AUTOSAR XML (schema 00049)
package /Application/DltConfig
  dlt log channel to process mapping DltLogChannelToProcessMapping_KATECH_TO_KATECH: dlt-log-channel=KATECH, process=KATECH
package /Application/Executable
  executable KATECH: category=APPLICATION_LEVEL, logging-behavior=USES-LOGGING, reporting-behavior=REPORTS-EXECUTION-STATE, version=1.0.0
    root sw component prototype AA: application-type=KATECH
package /Application/Manifest
  service instance to port prototype mapping KATECH_AA_RPortRearCurtain: port-prototype=AA.RPortRearCurtain, service-instance=EEVP_KATECH_Consumer_RearCurtain
  service instance to port prototype mapping KATECH_AA_RPortRoa: port-prototype=AA.RPortRoa, service-instance=EEVP_KATECH_Consumer_SoaRoa
  service instance to port prototype mapping KATECH_AA_RPortSubscriptionManagement: port-prototype=AA.RPortSubscriptionManagement, service-instance=EEVP_KATECH_Consumer_SubscriptionManagement
package /Application/Package/KATECH/SoftwareCluster_1_0_0
  software cluster KATECH_SoftwareCluster: category=APPLICATION_LAYER, contained-ar-element=KATECH, contained-package-element=[KATECH_AA_RPortRearCurtain, KATECH_AA_RPortRoa], contained-process=KATECH, vendor-id=102, vendor-signature=ParaCertificate, version=1.0.0
package /Application/Package/KATECH/SoftwarePackage
  software package KATECH_InstallSoftwarePackage_1_0_0: action-type=INSTALL, compressed-software-package-size=0, maximum-supported-ucm-version=1.0.0, minimum-supported-ucm-version=1.0.0, packager-id=102, packager-signature=ParaCertificate, post-verification-reboot=false, pre-activation-reboot=false, software-cluster=KATECH_SoftwareCluster, uncompressed-software-cluster-size=0
  software package KATECH_RemoveSoftwarePackage_1_0_0: action-type=REMOVE, compressed-software-package-size=0, maximum-supported-ucm-version=1.0.0, minimum-supported-ucm-version=1.0.0, packager-id=102, packager-signature=ParaCertificate, post-verification-reboot=false, pre-activation-reboot=false, software-cluster=KATECH_SoftwareCluster, uncompressed-software-cluster-size=0
  software package KATECH_UpdateSoftwarePackage_1_0_0: action-type=UPDATE, compressed-software-package-size=0, maximum-supported-ucm-version=1.0.0, minimum-supported-ucm-version=1.0.0, packager-id=102, packager-signature=ParaCertificate, post-verification-reboot=false, pre-activation-reboot=false, software-cluster=KATECH_SoftwareCluster, uncompressed-software-cluster-size=0
package /Application/Package/KATECH/VehiclePackage
  vehicle package KATECH_InstallVehiclePackage_1_0_0: vehicle-driver-notification{approval-required=true, notification-state=PROCESS}, packager-signature=ParaCertificate
    rollout-qualifications:
      vehicle rollout step RolloutQualification
        ucm-processings:
          ucm step UcmProcessing: ucm=KATECH_InstallVehiclePackage_1_0_0/EEVP_UCM
            software package step SoftwarePackageStep: process=KATECH_InstallSoftwarePackage_1_0_0, transfers=software-package-storing={storing=UCM, transfer=KATECH_InstallSoftwarePackage_1_0_0}
    ucm description EEVP_UCM: identifier=EEVP_UCM
  vehicle package KATECH_RemoveVehiclePackage_1_0_0: vehicle-driver-notification{approval-required=true, notification-state=PROCESS}, packager-signature=ParaCertificate
    rollout-qualifications:
      vehicle rollout step RolloutQualification
        ucm-processings:
          ucm step UcmProcessing: ucm=KATECH_RemoveVehiclePackage_1_0_0/EEVP_UCM
            software package step SoftwarePackageStep: process=KATECH_RemoveSoftwarePackage_1_0_0, transfers=software-package-storing={storing=UCM, transfer=KATECH_RemoveSoftwarePackage_1_0_0}
    ucm description EEVP_UCM: identifier=EEVP_UCM
  vehicle package KATECH_UpdateVehiclePackage_1_0_0: vehicle-driver-notification{approval-required=true, notification-state=PROCESS}, packager-signature=ParaCertificate
    rollout-qualifications:
      vehicle rollout step RolloutQualification
        ucm-processings:
          ucm step UcmProcessing: ucm=KATECH_UpdateVehiclePackage_1_0_0/EEVP_UCM
            software package step SoftwarePackageStep: process=KATECH_UpdateSoftwarePackage_1_0_0, transfers=software-package-storing={storing=UCM, transfer=KATECH_UpdateSoftwarePackage_1_0_0}
    ucm description EEVP_UCM: identifier=EEVP_UCM
package /Application/Process
  process KATECH: executable=KATECH, state-dependent-startup-config{execution-dependency=CM.Running, function-group-state=[SFG01.On, SFG01.Verify], resource-group=DefaultResourceGroup, startup-config=DefaultStartupConfig}
    process state machine KATECH: type=ProcessState
package /Application/SwComponent
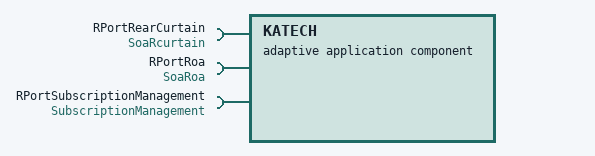
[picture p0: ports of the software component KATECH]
  adaptive application sw component type KATECH
    require port RPortRearCurtain: required-interface=SoaRcurtain
    require port RPortRoa: required-interface=SoaRoa
    require port RPortSubscriptionManagement: required-interface=SubscriptionManagement
